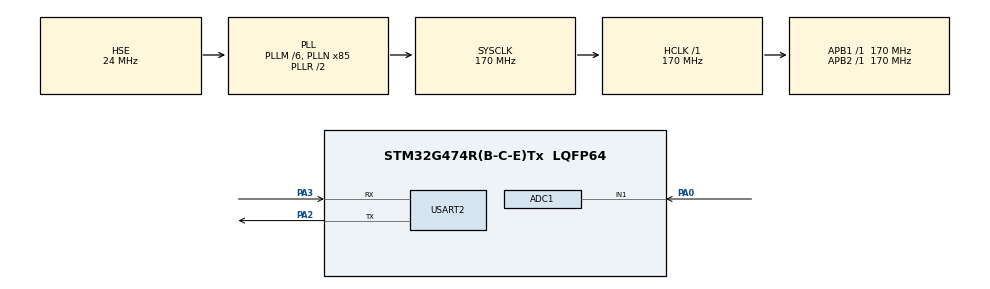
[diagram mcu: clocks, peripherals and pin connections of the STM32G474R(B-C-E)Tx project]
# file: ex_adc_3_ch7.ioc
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Mcu.Family=STM32G4
RCC.PLLSourceVirtual=RCC_PLLSOURCE_HSE
NVIC.ADC1_2_IRQn=true\:1\:0\:true\:false\:true\:true\:true
PA2.GPIO_PuPd=GPIO_PULLUP
RCC.CortexFreq_Value=170000000
ADC1.Rank-0\#ChannelRegularConversion=1
ADC1.OffsetNumber-0\#ChannelRegularConversion=ADC_OFFSET_NONE
PA3.GPIO_PuPd=GPIO_PULLUP
RCC.EXTERNAL_CLOCK_VALUE=12288000
NVIC.USART2_IRQn=true\:0\:0\:false\:false\:true\:true\:true
RCC.SYSCLKSource=RCC_SYSCLKSOURCE_PLLCLK
ProjectManager.StackSize=0x400
PA13.Signal=SYS_JTMS-SWDIO
PA3.Mode=Asynchronous
ProjectManager.TargetToolchain=STM32CubeIDE
RCC.HCLKFreq_Value=170000000
RCC.APB2TimFreq_Value=170000000
RCC.USBFreq_Value=170000000
RCC.LSE_VALUE=32768
RCC.AHBFreq_Value=170000000
PF0-OSC_IN.Mode=HSE-External-Oscillator
ADC1.Channel-0\#ChannelRegularConversion=ADC_CHANNEL_1
RCC.HSE_VALUE=24000000
board=custom
USART2.VirtualMode-Asynchronous=VM_ASYNC
RCC.VCOOutputFreq_Value=340000000
RCC.ADC12Freq_Value=34000000
NVIC.TIM3_IRQn=true\:0\:0\:false\:false\:true\:true\:true
RCC.ADC345Freq_Value=170000000
RCC.APB2Freq_Value=170000000
PA14.Mode=Serial_Wire
TIM3.Prescaler=169
PA0.Mode=IN1-Single-Ended
VP_SYS_VS_DBSignals.Mode=DisableDeadBatterySignals
PA13.Mode=Serial_Wire
Mcu.Name=STM32G474R(B-C-E)Tx
ADC1.SamplingTime-0\#ChannelRegularConversion=ADC_SAMPLETIME_2CYCLES_5
PA2.Signal=USART2_TX
PA0.Signal=ADC1_IN1
ADC1.ExternalTrigConv=ADC_EXTERNALTRIG_T3_TRGO
RCC.SYSCLKFreq_VALUE=170000000
Mcu.Package=LQFP64
ADC1.master=1
RCC.ADC12CLockSelection=RCC_ADC12CLKSOURCE_PLL
PA14.Signal=SYS_JTCK-SWCLK
ProjectManager.HeapSize=0x200
TIM3.PeriodNoDither=999
RCC.HSI_VALUE=16000000
RCC.PLLP=RCC_PLLP_DIV10
NVIC.PriorityGroup=NVIC_PRIORITYGROUP_4
ADC1.NbrOfConversionFlag=1
RCC.PLLM=RCC_PLLM_DIV6
RCC.PLLN=85
RCC.APB1TimFreq_Value=170000000
PA2.Mode=Asynchronous
PF0-OSC_IN.Signal=RCC_OSC_IN
TIM3.TIM_MasterOutputTrigger=TIM_TRGO_UPDATE
PF1-OSC_OUT.Mode=HSE-External-Oscillator
RCC.APB1Freq_Value=170000000
ADC1.ClockPrescaler=ADC_CLOCK_ASYNC_DIV1
VP_TIM3_VS_ClockSourceINT.Mode=Internal
PF1-OSC_OUT.Signal=RCC_OSC_OUT
RCC.HSI48_VALUE=48000000
PA3.Signal=USART2_RX

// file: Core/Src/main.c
/* USER CODE BEGIN Header */
/**
  ******************************************************************************
  * @file           : main.c
  * @brief          : Main program body
  ******************************************************************************
  * @attention
  *
  * <h2><center>&copy; Copyright (c) 2022 STMicroelectronics.
  * All rights reserved.</center></h2>
  *
  * This software component is licensed by ST under BSD 3-Clause license,
  * the "License"; You may not use this file except in compliance with the
  * License. You may obtain a copy of the License at:
  *                        opensource.org/licenses/BSD-3-Clause
  *
  ******************************************************************************
  */
/* USER CODE END Header */
#include "main.h"

/* USER CODE BEGIN Includes */
#include "stdio.h"
#include "stdlib.h"
#include "string.h"
/* USER CODE END Includes */

/* USER CODE BEGIN PD */
#define ADC_CONVERTED_DATA_BUFFER_SIZE (uint16_t)65

// 7.3
//#define RX_BUFFER_SIZE 8

// 7.4
#define RX_BUFFER_SIZE 6

/* USER CODE END PD */

ADC_HandleTypeDef hadc1;

TIM_HandleTypeDef htim3;

UART_HandleTypeDef huart2;

/* USER CODE BEGIN PV */
uint16_t ADC1ConvertedData[ADC_CONVERTED_DATA_BUFFER_SIZE];
uint16_t ADC1Data_index = 0;
uint8_t ADCSampleFlag = 0;

uint8_t RxBuffer[RX_BUFFER_SIZE] = {0};
uint8_t CommFlag = 0;
uint8_t StartMsg[] = "Start sample!\r\n";
uint8_t SampleStr[7] = "Sample";

/* USER CODE END PV */

void SystemClock_Config(void);
static void MX_GPIO_Init(void);
static void MX_ADC1_Init(void);
static void MX_TIM3_Init(void);
static void MX_USART2_UART_Init(void);

int main(void)
{

  /* MCU Configuration--------------------------------------------------------*/

  /* Reset of all peripherals, Initializes the Flash interface and the Systick. */
  HAL_Init();

  /* Configure the system clock */
  SystemClock_Config();

  /* Initialize all configured peripherals */
  MX_GPIO_Init();
  MX_ADC1_Init();
  MX_TIM3_Init();
  MX_USART2_UART_Init();
  /* USER CODE BEGIN 2 */
  HAL_ADCEx_Calibration_Start(&hadc1, ADC_SINGLE_ENDED);
  HAL_ADC_Start_IT(&hadc1);
  HAL_TIM_Base_Start(&htim3);
  HAL_UART_Receive_IT(&huart2, (uint8_t *)RxBuffer, RX_BUFFER_SIZE);

  /* USER CODE END 2 */

  /* Infinite loop */
  while (1)
  {

    /* USER CODE BEGIN 3 */

	  // 7.3
//	  printf("test msg\r\n");
//	  if((ADCSampleFlag == 1) && (CommFlag == 1) && (RxBuffer[0] == 0x53) && (RxBuffer[7] == 0x45)){
//
//		  uint8_t check = 1;
//		  for (uint32_t i = 1; i <= 5; ++i){
//			  if (RxBuffer[i] != SampleStr[i-1]) {
//				  check = 0;
//			  }
//		  }
//		  if (check > 0){
//			  for(uint16_t i = 1; i < ADC_CONVERTED_DATA_BUFFER_SIZE; i++)
//			  {
//				  printf("ADC1ConvertedData[%d] = %d\r\n", i, ADC1ConvertedData[i]);
//			  }
//			  HAL_Delay(1000);
//		  }
//		  else {
//			  printf("invalid info.\r\n");
//		  }
//		  CommFlag = 0;
//		  ADCSampleFlag = 0;
//	  }

	  // 7.4
	  if((ADCSampleFlag == 1) && (CommFlag == 1) && (RxBuffer[0] == 0x53) && (RxBuffer[5] == 0x45)){

		  	  uint16_t val_q = 0;
		  	  uint16_t min_val_s = 5000;
		  	  uint16_t max_val_s = 0;

		  	  for (uint8_t i = 1; i < 5; ++i){
		  		  val_q = val_q * 10 + (RxBuffer[i] - 48);
		  	  }

		  	  for (uint8_t i = 0; i < ADC_CONVERTED_DATA_BUFFER_SIZE; ++i){
		  		  uint16_t val = ADC1ConvertedData[i];

		  		  if (val < min_val_s){
		  			  min_val_s = val;
		  		  }
		  		  if (val > max_val_s){
		  			  max_val_s = val;
		  		  }
		  	  }
		  	  uint16_t *val_cnt = (uint16_t *)malloc((max_val_s - min_val_s + 1)*sizeof(uint16_t));
		  	  for (uint8_t i = 0; i < max_val_s - min_val_s + 1; ++i){
		  		  val_cnt[i] = 0;
		  	  }

		  	  for (uint8_t i = 0; i < ADC_CONVERTED_DATA_BUFFER_SIZE; ++i){
		  		  uint16_t val = ADC1ConvertedData[i];
		  		  val_cnt[val - min_val_s]++;
		  	  }

		  	  uint16_t cnt_q = (val_q >= min_val_s && val_q <= max_val_s) ? val_cnt[val_q - min_val_s] : 0;
		  	  printf("count of query value %d : %d \r\n", (int)val_q, (int)cnt_q);

		  	  printf("counts of all sample value:\r\n");
		  	  for (uint8_t i = 0; i < max_val_s - min_val_s + 1; ++i){
		  		  if (val_cnt[i] > 0){
		  			  printf("val: %d cnt: %d\r\n", (int)(min_val_s+i), val_cnt[i]);
		  		  }
		  	  }

			  CommFlag = 0;
			  ADCSampleFlag = 0;
		  }
  }
  /* USER CODE END 3 */
}

void SystemClock_Config(void)
{
  RCC_OscInitTypeDef RCC_OscInitStruct = {0};
  RCC_ClkInitTypeDef RCC_ClkInitStruct = {0};
  RCC_PeriphCLKInitTypeDef PeriphClkInit = {0};

  /** Configure the main internal regulator output voltage
  */
  HAL_PWREx_ControlVoltageScaling(PWR_REGULATOR_VOLTAGE_SCALE1_BOOST);
  /** Initializes the RCC Oscillators according to the specified parameters
  * in the RCC_OscInitTypeDef structure.
  */
  RCC_OscInitStruct.OscillatorType = RCC_OSCILLATORTYPE_HSE;
  RCC_OscInitStruct.HSEState = RCC_HSE_ON;
  RCC_OscInitStruct.PLL.PLLState = RCC_PLL_ON;
  RCC_OscInitStruct.PLL.PLLSource = RCC_PLLSOURCE_HSE;
  RCC_OscInitStruct.PLL.PLLM = RCC_PLLM_DIV6;
  RCC_OscInitStruct.PLL.PLLN = 85;
  RCC_OscInitStruct.PLL.PLLP = RCC_PLLP_DIV10;
  RCC_OscInitStruct.PLL.PLLQ = RCC_PLLQ_DIV2;
  RCC_OscInitStruct.PLL.PLLR = RCC_PLLR_DIV2;
  if (HAL_RCC_OscConfig(&RCC_OscInitStruct) != HAL_OK)
  {
    Error_Handler();
  }
  /** Initializes the CPU, AHB and APB buses clocks
  */
  RCC_ClkInitStruct.ClockType = RCC_CLOCKTYPE_HCLK|RCC_CLOCKTYPE_SYSCLK
                              |RCC_CLOCKTYPE_PCLK1|RCC_CLOCKTYPE_PCLK2;
  RCC_ClkInitStruct.SYSCLKSource = RCC_SYSCLKSOURCE_PLLCLK;
  RCC_ClkInitStruct.AHBCLKDivider = RCC_SYSCLK_DIV1;
  RCC_ClkInitStruct.APB1CLKDivider = RCC_HCLK_DIV1;
  RCC_ClkInitStruct.APB2CLKDivider = RCC_HCLK_DIV1;

  if (HAL_RCC_ClockConfig(&RCC_ClkInitStruct, FLASH_LATENCY_4) != HAL_OK)
  {
    Error_Handler();
  }
  /** Initializes the peripherals clocks
  */
  PeriphClkInit.PeriphClockSelection = RCC_PERIPHCLK_USART2|RCC_PERIPHCLK_ADC12;
  PeriphClkInit.Usart2ClockSelection = RCC_USART2CLKSOURCE_PCLK1;
  PeriphClkInit.Adc12ClockSelection = RCC_ADC12CLKSOURCE_PLL;
  if (HAL_RCCEx_PeriphCLKConfig(&PeriphClkInit) != HAL_OK)
  {
    Error_Handler();
  }
}

static void MX_ADC1_Init(void)
{

  ADC_MultiModeTypeDef multimode = {0};
  ADC_ChannelConfTypeDef sConfig = {0};

  /** Common config
  */
  hadc1.Instance = ADC1;
  hadc1.Init.ClockPrescaler = ADC_CLOCK_ASYNC_DIV1;
  hadc1.Init.Resolution = ADC_RESOLUTION_12B;
  hadc1.Init.DataAlign = ADC_DATAALIGN_RIGHT;
  hadc1.Init.GainCompensation = 0;
  hadc1.Init.ScanConvMode = ADC_SCAN_DISABLE;
  hadc1.Init.EOCSelection = ADC_EOC_SINGLE_CONV;
  hadc1.Init.LowPowerAutoWait = DISABLE;
  hadc1.Init.ContinuousConvMode = DISABLE;
  hadc1.Init.NbrOfConversion = 1;
  hadc1.Init.DiscontinuousConvMode = DISABLE;
  hadc1.Init.ExternalTrigConv = ADC_EXTERNALTRIG_T3_TRGO;
  hadc1.Init.ExternalTrigConvEdge = ADC_EXTERNALTRIGCONVEDGE_RISING;
  hadc1.Init.DMAContinuousRequests = DISABLE;
  hadc1.Init.Overrun = ADC_OVR_DATA_PRESERVED;
  hadc1.Init.OversamplingMode = DISABLE;
  if (HAL_ADC_Init(&hadc1) != HAL_OK)
  {
    Error_Handler();
  }
  /** Configure the ADC multi-mode
  */
  multimode.Mode = ADC_MODE_INDEPENDENT;
  if (HAL_ADCEx_MultiModeConfigChannel(&hadc1, &multimode) != HAL_OK)
  {
    Error_Handler();
  }
  /** Configure Regular Channel
  */
  sConfig.Channel = ADC_CHANNEL_1;
  sConfig.Rank = ADC_REGULAR_RANK_1;
  sConfig.SamplingTime = ADC_SAMPLETIME_2CYCLES_5;
  sConfig.SingleDiff = ADC_SINGLE_ENDED;
  sConfig.OffsetNumber = ADC_OFFSET_NONE;
  sConfig.Offset = 0;
  if (HAL_ADC_ConfigChannel(&hadc1, &sConfig) != HAL_OK)
  {
    Error_Handler();
  }

}

static void MX_TIM3_Init(void)
{

  TIM_ClockConfigTypeDef sClockSourceConfig = {0};
  TIM_MasterConfigTypeDef sMasterConfig = {0};

  htim3.Instance = TIM3;
  htim3.Init.Prescaler = 169;
  htim3.Init.CounterMode = TIM_COUNTERMODE_UP;
  htim3.Init.Period = 999;
  htim3.Init.ClockDivision = TIM_CLOCKDIVISION_DIV1;
  htim3.Init.AutoReloadPreload = TIM_AUTORELOAD_PRELOAD_DISABLE;
  if (HAL_TIM_Base_Init(&htim3) != HAL_OK)
  {
    Error_Handler();
  }
  sClockSourceConfig.ClockSource = TIM_CLOCKSOURCE_INTERNAL;
  if (HAL_TIM_ConfigClockSource(&htim3, &sClockSourceConfig) != HAL_OK)
  {
    Error_Handler();
  }
  sMasterConfig.MasterOutputTrigger = TIM_TRGO_UPDATE;
  sMasterConfig.MasterSlaveMode = TIM_MASTERSLAVEMODE_DISABLE;
  if (HAL_TIMEx_MasterConfigSynchronization(&htim3, &sMasterConfig) != HAL_OK)
  {
    Error_Handler();
  }

}

static void MX_USART2_UART_Init(void)
{

  huart2.Instance = USART2;
  huart2.Init.BaudRate = 115200;
  huart2.Init.WordLength = UART_WORDLENGTH_8B;
  huart2.Init.StopBits = UART_STOPBITS_1;
  huart2.Init.Parity = UART_PARITY_NONE;
  huart2.Init.Mode = UART_MODE_TX_RX;
  huart2.Init.HwFlowCtl = UART_HWCONTROL_NONE;
  huart2.Init.OverSampling = UART_OVERSAMPLING_16;
  huart2.Init.OneBitSampling = UART_ONE_BIT_SAMPLE_DISABLE;
  huart2.Init.ClockPrescaler = UART_PRESCALER_DIV1;
  huart2.AdvancedInit.AdvFeatureInit = UART_ADVFEATURE_NO_INIT;
  if (HAL_UART_Init(&huart2) != HAL_OK)
  {
    Error_Handler();
  }
  if (HAL_UARTEx_SetTxFifoThreshold(&huart2, UART_TXFIFO_THRESHOLD_1_8) != HAL_OK)
  {
    Error_Handler();
  }
  if (HAL_UARTEx_SetRxFifoThreshold(&huart2, UART_RXFIFO_THRESHOLD_1_8) != HAL_OK)
  {
    Error_Handler();
  }
  if (HAL_UARTEx_DisableFifoMode(&huart2) != HAL_OK)
  {
    Error_Handler();
  }

}

static void MX_GPIO_Init(void)
{

  /* GPIO Ports Clock Enable */
  __HAL_RCC_GPIOF_CLK_ENABLE();
  __HAL_RCC_GPIOA_CLK_ENABLE();

}

/* USER CODE BEGIN 4 */
void HAL_ADC_ConvCpltCallback(ADC_HandleTypeDef *hadc)
{
	ADC1ConvertedData[ADC1Data_index] = HAL_ADC_GetValue(&hadc1);
	if (ADCSampleFlag == 0)
		ADC1Data_index++;
	if (ADC1Data_index == ADC_CONVERTED_DATA_BUFFER_SIZE)
	{
		ADCSampleFlag = 1;
		ADC1Data_index = 0;
	}
}
int __io_putchar(int ch)
{
	HAL_UART_Transmit(&huart2, (uint8_t *)&ch, 1, 0xFFFF);
	return ch;
}

void HAL_UART_RxCpltCallback(UART_HandleTypeDef *huart)
{
	CommFlag = 1;
	HAL_UART_Receive_IT(&huart2, (uint8_t *)RxBuffer, RX_BUFFER_SIZE);
}
/* USER CODE END 4 */

void Error_Handler(void)
{
  __disable_irq();
  while (1)
  {
  }
}

/************************ (C) COPYRIGHT STMicroelectronics *****END OF FILE****/
